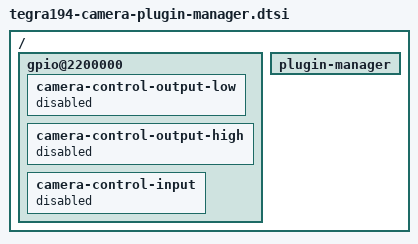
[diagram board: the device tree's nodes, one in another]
/*
 * Copyright (c) 2016-2021, NVIDIA CORPORATION.  All rights reserved.
 *
 * This program is free software; you can redistribute it and/or modify
 * it under the terms of the GNU General Public License as published by
 * the Free Software Foundation; version 2 of the License.
 *
 * This program is distributed in the hope that it will be useful, but WITHOUT
 * ANY WARRANTY; without even the implied warranty of MERCHANTABILITY or
 * FITNESS FOR A PARTICULAR PURPOSE.  See the GNU General Public License for
 * more details.
 *
 */

#define CAM0_RST_L	TEGRA194_MAIN_GPIO(H, 3)
#define CAM0_PWDN	TEGRA194_MAIN_GPIO(H, 6)
#define CAM1_RST_L	TEGRA194_MAIN_GPIO(T, 6)
#define CAM1_PWDN	TEGRA194_MAIN_GPIO(T, 5)
#define SLVS_CAM0_RST_L	TEGRA194_MAIN_GPIO(Y, 1)

/ {
	gpio@2200000 {
		camera-control-output-low {
			status = "disabled";
		};

		camera-control-output-high {
			status = "disabled";
		};

		camera-control-input {
			status = "disabled";
		};
	};

	/* camera plugin-manager */
	plugin-manager {
	};
};
